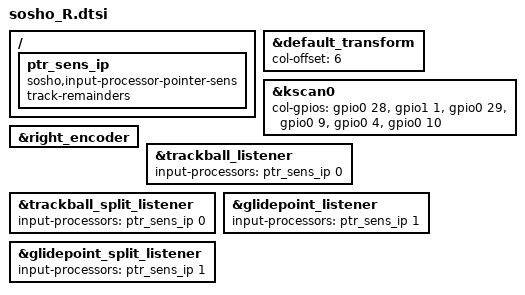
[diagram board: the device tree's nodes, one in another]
#include "sosho.dtsi"
#include <dt-bindings/zmk/input_transform.h>
#include <input/processors.dtsi>

&default_transform {
    col-offset = <6>;
};

&kscan0 {
    col-gpios
        = <&gpio0 28 GPIO_ACTIVE_HIGH>
        , <&gpio1 1  GPIO_ACTIVE_HIGH> 
        , <&gpio0 29 GPIO_ACTIVE_HIGH> 
        , <&gpio0 9  GPIO_ACTIVE_HIGH> 
        , <&gpio0 4  GPIO_ACTIVE_HIGH>
        , <&gpio0 10 GPIO_ACTIVE_HIGH>
        ;
};

&right_encoder{
    status =  "okay";
};

/* ポインタ感度。値はキーマップの設定用レイヤー(&ptr_sens)から読む。
   引数はスロット番号: 0 = トラックボール、1 = トラックパッド */
/ {
    ptr_sens_ip: ptr_sens_ip {
        compatible = "sosho,input-processor-pointer-sens";
        #input-processor-cells = <1>;
        track-remainders;
    };
};

&trackball_listener        { input-processors = <&ptr_sens_ip 0>; };
&trackball_split_listener  { input-processors = <&ptr_sens_ip 0>; };
&glidepoint_listener       { input-processors = <&ptr_sens_ip 1>; };
&glidepoint_split_listener { input-processors = <&ptr_sens_ip 1>; };
